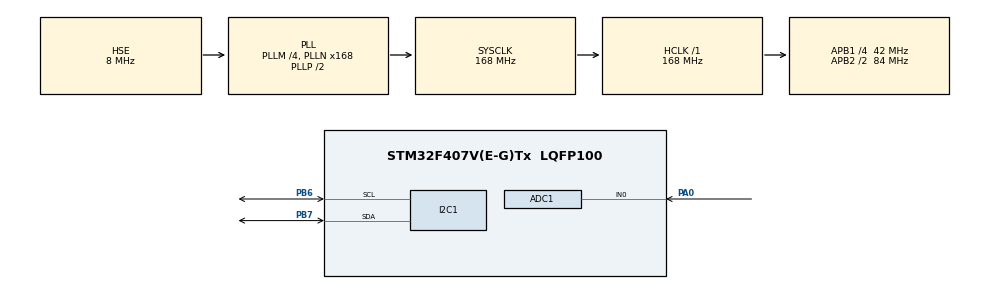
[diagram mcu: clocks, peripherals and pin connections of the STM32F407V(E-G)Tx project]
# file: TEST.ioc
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ADC1.Channel-0\#ChannelRegularConversion=ADC_CHANNEL_0
ADC1.NbrOfConversionFlag=1
ADC1.Rank-0\#ChannelRegularConversion=1
ADC1.SamplingTime-0\#ChannelRegularConversion=ADC_SAMPLETIME_3CYCLES
ADC1.master=1
Mcu.Family=STM32F4
Mcu.Name=STM32F407V(E-G)Tx
Mcu.Package=LQFP100
NVIC.PriorityGroup=NVIC_PRIORITYGROUP_4
PA0-WKUP.Signal=ADCx_IN0
PB6.Mode=I2C
PB6.Signal=I2C1_SCL
PB7.Mode=I2C
PB7.Signal=I2C1_SDA
PH0-OSC_IN.Mode=HSE-External-Oscillator
PH0-OSC_IN.Signal=RCC_OSC_IN
PH1-OSC_OUT.Mode=HSE-External-Oscillator
PH1-OSC_OUT.Signal=RCC_OSC_OUT
ProjectManager.HeapSize=0x200
ProjectManager.StackSize=0x400
ProjectManager.TargetToolchain=MDK-ARM V5.27
RCC.48MHZClocksFreq_Value=84000000
RCC.AHBFreq_Value=168000000
RCC.APB1CLKDivider=RCC_HCLK_DIV4
RCC.APB1Freq_Value=42000000
RCC.APB1TimFreq_Value=84000000
RCC.APB2CLKDivider=RCC_HCLK_DIV2
RCC.APB2Freq_Value=84000000
RCC.APB2TimFreq_Value=168000000
RCC.CortexFreq_Value=168000000
RCC.HCLKFreq_Value=168000000
RCC.HSE_VALUE=8000000
RCC.HSI_VALUE=16000000
RCC.LSE_VALUE=32768
RCC.PLLM=4
RCC.PLLN=168
RCC.PLLSourceVirtual=RCC_PLLSOURCE_HSE
RCC.SYSCLKFreq_VALUE=168000000
RCC.SYSCLKSource=RCC_SYSCLKSOURCE_PLLCLK
RCC.VCOOutputFreq_Value=336000000
SH.ADCx_IN0.0=ADC1_IN0,IN0
board=custom

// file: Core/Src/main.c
/* USER CODE BEGIN Header */
/**
  ******************************************************************************
  * @file           : main.c
  * @brief          : Main program body
  ******************************************************************************
  * @attention
  *
  * Copyright (c) 2023 STMicroelectronics.
  * All rights reserved.
  *
  * This software is licensed under terms that can be found in the LICENSE file
  * in the root directory of this software component.
  * If no LICENSE file comes with this software, it is provided AS-IS.
  *
  ******************************************************************************
  */
/* USER CODE END Header */
#include "main.h"

/* USER CODE BEGIN Includes */
#include "CLCD_I2C.h"
#include "stdio.h"
#include "stdlib.h"
#include "string.h"
#include <stdint.h>
/* USER CODE END Includes */

ADC_HandleTypeDef hadc1;

I2C_HandleTypeDef hi2c1;

/* USER CODE BEGIN PV */
	CLCD_I2C_Name LCD1;
	#define SENSOR_PIN GPIO_PIN_0
	#define SENSOR_PORT GPIOA

	// khoi tao bien de luu gia tri do duoc tu cam bien
	uint16_t sensorValue = 0;
	float pressureValue = 0;
	float DC_gain = 220;
	float adc_data = 0;

/* USER CODE END PV */

void SystemClock_Config(void);
static void MX_GPIO_Init(void);
static void MX_ADC1_Init(void);
static void MX_I2C1_Init(void);

int main(void)
{

  /* MCU Configuration--------------------------------------------------------*/

  /* Reset of all peripherals, Initializes the Flash interface and the Systick. */
  HAL_Init();

  /* Configure the system clock */
  SystemClock_Config();

  /* Initialize all configured peripherals */
  MX_GPIO_Init();
  MX_ADC1_Init();
  MX_I2C1_Init();
  /* USER CODE BEGIN 2 */
	CLCD_I2C_Init(&LCD1, &hi2c1, 0x4e,20,4);
  /* USER CODE END 2 */

  /* Infinite loop */
  /* USER CODE BEGIN WHILE */
  while (1)
  {
		// Doc gia tri cam bien MPS20N0040D
        HAL_ADC_Start(&hadc1); //
        HAL_ADC_PollForConversion(&hadc1, 10);
				float data = HAL_ADC_GetValue(&hadc1);	//lр giс tri VXL doc duoc tu ADC0
				float adc_data = (data  ) / 1023; 			//giс tri dien ap  vрo chan ADC0
				// tinh toan va xuat ra huyet ap tam thu
				char lcdString[16];
				// huyet ap tam thu
				float sys = (adc_data / DC_gain) * 12001;
				// huyet ap tam truong
				float dias = sys - (sys - 80)* 2/3 ; // huyet ap dong mach = 80;
				//	huyet ap trung binh
				float MAP = dias + (sys - dias) / 3;
				//ap suat do duoc P = (V - Vmin) / (Vmax - Vmin) x (Pmax - Pmin) + Pmin
				/*
					V = dien ap do duoc tu ADC
					Vmax = 25*10^(-3) * 220;
					Pmax = 40KPa

				*/
				float pressure = ((adc_data - 0) / (5 - 0) * (40 - 0) + 0);

				sprintf(lcdString, "sys = %5.2f",sys );
				CLCD_I2C_SetCursor(&LCD1, 0, 0);
				CLCD_I2C_WriteString(&LCD1, lcdString);
				CLCD_I2C_WriteString(&LCD1," mmHg");

				sprintf(lcdString, "dias = %5.2f",dias );
				CLCD_I2C_SetCursor(&LCD1, 0, 1);
				CLCD_I2C_WriteString(&LCD1, lcdString);
				CLCD_I2C_WriteString(&LCD1," mmHg");

				sprintf(lcdString, "MAP = %5.2f",MAP );
				CLCD_I2C_SetCursor(&LCD1, 0, 2);
				CLCD_I2C_WriteString(&LCD1, lcdString);
				CLCD_I2C_WriteString(&LCD1," mmHg");

				sprintf(lcdString, "P = %5.2f",pressure );
				CLCD_I2C_SetCursor(&LCD1, 0, 4);
				CLCD_I2C_WriteString(&LCD1, lcdString);
				CLCD_I2C_WriteString(&LCD1," KPa");

    /* USER CODE END WHILE */

  }
}

void SystemClock_Config(void)
{
  RCC_OscInitTypeDef RCC_OscInitStruct = {0};
  RCC_ClkInitTypeDef RCC_ClkInitStruct = {0};

  /** Configure the main internal regulator output voltage
  */
  __HAL_RCC_PWR_CLK_ENABLE();
  __HAL_PWR_VOLTAGESCALING_CONFIG(PWR_REGULATOR_VOLTAGE_SCALE1);

  /** Initializes the RCC Oscillators according to the specified parameters
  * in the RCC_OscInitTypeDef structure.
  */
  RCC_OscInitStruct.OscillatorType = RCC_OSCILLATORTYPE_HSE;
  RCC_OscInitStruct.HSEState = RCC_HSE_ON;
  RCC_OscInitStruct.PLL.PLLState = RCC_PLL_ON;
  RCC_OscInitStruct.PLL.PLLSource = RCC_PLLSOURCE_HSE;
  RCC_OscInitStruct.PLL.PLLM = 4;
  RCC_OscInitStruct.PLL.PLLN = 168;
  RCC_OscInitStruct.PLL.PLLP = RCC_PLLP_DIV2;
  RCC_OscInitStruct.PLL.PLLQ = 4;
  if (HAL_RCC_OscConfig(&RCC_OscInitStruct) != HAL_OK)
  {
    Error_Handler();
  }

  /** Initializes the CPU, AHB and APB buses clocks
  */
  RCC_ClkInitStruct.ClockType = RCC_CLOCKTYPE_HCLK|RCC_CLOCKTYPE_SYSCLK
                              |RCC_CLOCKTYPE_PCLK1|RCC_CLOCKTYPE_PCLK2;
  RCC_ClkInitStruct.SYSCLKSource = RCC_SYSCLKSOURCE_PLLCLK;
  RCC_ClkInitStruct.AHBCLKDivider = RCC_SYSCLK_DIV1;
  RCC_ClkInitStruct.APB1CLKDivider = RCC_HCLK_DIV4;
  RCC_ClkInitStruct.APB2CLKDivider = RCC_HCLK_DIV2;

  if (HAL_RCC_ClockConfig(&RCC_ClkInitStruct, FLASH_LATENCY_5) != HAL_OK)
  {
    Error_Handler();
  }
}

static void MX_ADC1_Init(void)
{

  ADC_ChannelConfTypeDef sConfig = {0};

  /** Configure the global features of the ADC (Clock, Resolution, Data Alignment and number of conversion)
  */
  hadc1.Instance = ADC1;
  hadc1.Init.ClockPrescaler = ADC_CLOCK_SYNC_PCLK_DIV4;
  hadc1.Init.Resolution = ADC_RESOLUTION_12B;
  hadc1.Init.ScanConvMode = DISABLE;
  hadc1.Init.ContinuousConvMode = DISABLE;
  hadc1.Init.DiscontinuousConvMode = DISABLE;
  hadc1.Init.ExternalTrigConvEdge = ADC_EXTERNALTRIGCONVEDGE_NONE;
  hadc1.Init.ExternalTrigConv = ADC_SOFTWARE_START;
  hadc1.Init.DataAlign = ADC_DATAALIGN_RIGHT;
  hadc1.Init.NbrOfConversion = 1;
  hadc1.Init.DMAContinuousRequests = DISABLE;
  hadc1.Init.EOCSelection = ADC_EOC_SINGLE_CONV;
  if (HAL_ADC_Init(&hadc1) != HAL_OK)
  {
    Error_Handler();
  }

  /** Configure for the selected ADC regular channel its corresponding rank in the sequencer and its sample time.
  */
  sConfig.Channel = ADC_CHANNEL_0;
  sConfig.Rank = 1;
  sConfig.SamplingTime = ADC_SAMPLETIME_3CYCLES;
  if (HAL_ADC_ConfigChannel(&hadc1, &sConfig) != HAL_OK)
  {
    Error_Handler();
  }

}

static void MX_I2C1_Init(void)
{

  hi2c1.Instance = I2C1;
  hi2c1.Init.ClockSpeed = 100000;
  hi2c1.Init.DutyCycle = I2C_DUTYCYCLE_2;
  hi2c1.Init.OwnAddress1 = 0;
  hi2c1.Init.AddressingMode = I2C_ADDRESSINGMODE_7BIT;
  hi2c1.Init.DualAddressMode = I2C_DUALADDRESS_DISABLE;
  hi2c1.Init.OwnAddress2 = 0;
  hi2c1.Init.GeneralCallMode = I2C_GENERALCALL_DISABLE;
  hi2c1.Init.NoStretchMode = I2C_NOSTRETCH_DISABLE;
  if (HAL_I2C_Init(&hi2c1) != HAL_OK)
  {
    Error_Handler();
  }

}

static void MX_GPIO_Init(void)
{

  /* GPIO Ports Clock Enable */
  __HAL_RCC_GPIOH_CLK_ENABLE();
  __HAL_RCC_GPIOA_CLK_ENABLE();
  __HAL_RCC_GPIOB_CLK_ENABLE();

}

void Error_Handler(void)
{
  __disable_irq();
  while (1)
  {
  }
}
